# AVR32SD28 register map
Vendor: Atmel; File version: 1.0
CPU: other r0p0, little endian, no MPU, no FPU, 4 interrupt priority bits
Registers are 8-bit, read-write, reset 0x0 unless marked. A register's access mark holds for its fields unless they carry their own. Offsets are from the block's base; [hi:lo] are bit positions; {n}, {i} and the like mark numbered series; 'fields as' and 'values as' point back to an identical list.

## TWI0 — Two-Wire Interface
Base 0x00800900
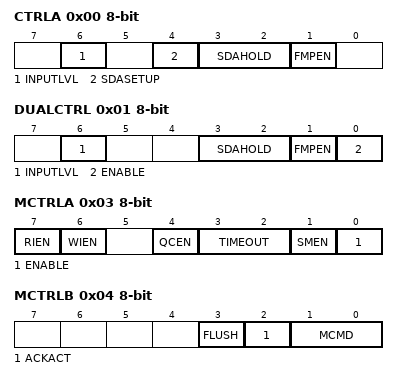
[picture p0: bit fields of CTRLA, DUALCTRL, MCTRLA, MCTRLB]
0x00 CTRLA — Control A
  [6] INPUTLVL — Input voltage transition level
    0=I2C (I2C input voltage transition level); 1=SMBUS (SMBus 3.0 input voltage transition level)
  [4] SDASETUP — SDA Setup Time
    0=4CYC (SDA setup time is four clock cycles); 1=8CYC (SDA setup time is eight clock cycle)
  [3:2] SDAHOLD — SDA Hold Time
    0=OFF (No SDA Hold Delay); 1=50NS (Short SDA hold time); 2=300NS (Meets SMBUS 2.0 specification under typical conditions); 3=500NS (Meets SMBUS 2.0 specificaiton across all corners)
  [1] FMPEN — Fast-mode Plus Enable
    0=OFF (Operating in Standard-mode or Fast-mode); 1=ON (Operating in Fast-mode Plus)
0x01 DUALCTRL — Dual Mode Control
  [6] INPUTLVL — Input voltage transition level
    values as CTRLA.INPUTLVL
  [3:2] SDAHOLD — SDA Hold Time
    values as CTRLA.SDAHOLD
  [1] FMPEN — Fast-mode Plus Enable
    values as CTRLA.FMPEN
  [0] ENABLE
0x02 DBGCTRL — Debug Control
  [0] DBGRUN — Debug Run
    0=HALT (The peripheral is halted in Break Debug mode and ignores events); 1=RUN (The peripheral will continue to run in Break Debug mode when the CPU is halted)
0x03 MCTRLA — Host Control A
  [7] RIEN — Read Interrupt Enable
  [6] WIEN — Write Interrupt Enable
  [4] QCEN — Quick Command Enable
  [3:2] TIMEOUT — Inactive Bus Time-Out
    0=DISABLED (Bus time-out disabled. I2C.); 1=50US (50us - SMBus); 2=100US; 3=200US
  [1] SMEN — Smart Mode Enable
  [0] ENABLE
0x04 MCTRLB — Host Control B
  [3] FLUSH
  [2] ACKACT — Acknowledge Action
    0=ACK (Send ACK); 1=NACK (Send NACK)
  [1:0] MCMD — Command
    0=NOACT (No action); 1=REPSTART (Execute Acknowledge Action followed by repeated Start.); 2=RECVTRANS (Execute Acknowledge Action followed by a byte read/write operation. Read/write is defined by DIR.); 3=STOP (Execute Acknowledge Action followed by issuing a Stop condition.)
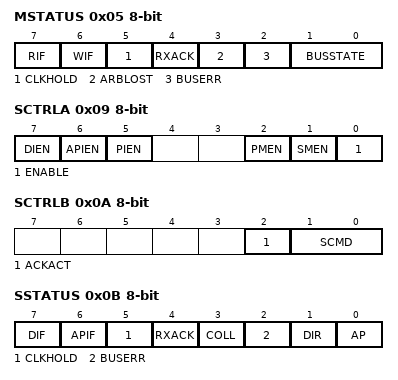
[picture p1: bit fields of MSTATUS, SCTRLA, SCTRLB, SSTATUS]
0x05 MSTATUS — Host STATUS
  [7] RIF — Read Interrupt Flag
  [6] WIF — Write Interrupt Flag
  [5] CLKHOLD — Clock Hold
  [4] RXACK ro — Received Acknowledge
  [3] ARBLOST — Arbitration Lost
  [2] BUSERR — Bus Error
  [1:0] BUSSTATE
    0=UNKNOWN (Unknown bus state); 1=IDLE (Bus is idle); 2=OWNER (This TWI controls the bus); 3=BUSY (The bus is busy)
0x06 MBAUD — Host Baud Rate
  [7:0] BAUD — Baud Rate
0x07 MADDR — Host Address
  [7:0] ADDR — Address
0x08 MDATA — Host Data
  [7:0] DATA
0x09 SCTRLA — Client Control A
  [7] DIEN — Data Interrupt Enable
  [6] APIEN — Address or Stop Interrupt Enable
  [5] PIEN — Stop Interrupt Enable
  [2] PMEN — Address Recognition Mode
  [1] SMEN — Smart Mode Enable
  [0] ENABLE
0x0A SCTRLB — Client Control B
  [2] ACKACT — Acknowledge Action
    0=ACK (Send ACK); 1=NACK (Send NACK)
  [1:0] SCMD — Command
    0=NOACT (No Action); 2=COMPTRANS (Complete transaction); 3=RESPONSE (Used in response to an interrupt)
0x0B SSTATUS — Client Status
  [7] DIF ro — Data Interrupt Flag
  [6] APIF ro — Address or Stop Interrupt Flag
  [5] CLKHOLD ro — Clock Hold
  [4] RXACK ro — Received Acknowledge
  [3] COLL — Collision
  [2] BUSERR — Bus Error
  [1] DIR ro — Read/Write Direction
  [0] AP ro — Address or Stop
    0=STOP (A Stop condition generated the interrupt on APIF flag); 1=ADR (Address detection generated the interrupt on APIF flag)
0x0C SADDR — Client Address
  [7:0] ADDR — Address
0x0D SDATA — Client Data
  [7:0] DATA
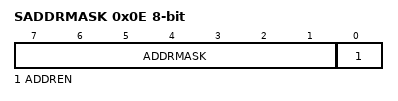
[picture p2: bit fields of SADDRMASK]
0x0E SADDRMASK — Client Address Mask
  [7:1] ADDRMASK — Address Mask
  [0] ADDREN — Address Mask Enable

## USART0 — Universal Synchronous and Asynchronous Receiver and Transmitter
Base 0x00800800
Same registers: USART1 0x00800820, USART2 0x00800840
0x00 RXDATAL ro — Receive Data Low Byte
  [7:0] DATA — RX Data
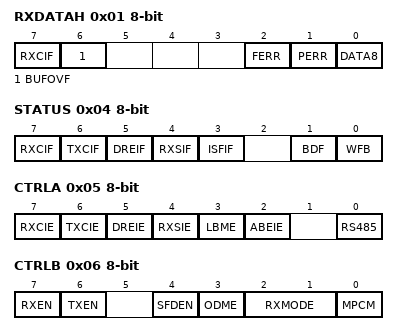
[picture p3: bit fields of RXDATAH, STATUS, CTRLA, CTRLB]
0x01 RXDATAH ro — Receive Data High Byte
  [7] RXCIF — Receive Complete Interrupt Flag
  [6] BUFOVF — Buffer Overflow
  [2] FERR — Frame Error
  [1] PERR — Parity Error
  [0] DATA8 — Receiver Data Register
0x02 TXDATAL — Transmit Data Low Byte
  [7:0] DATA — Transmit Data Register
0x03 TXDATAH — Transmit Data High Byte
  [0] DATA8 — Transmit Data Register (CHSIZE=9bit)
0x04 STATUS
  [7] RXCIF ro — Receive Complete Interrupt Flag
  [6] TXCIF — Transmit Interrupt Flag
  [5] DREIF ro — Data Register Empty Flag
  [4] RXSIF — Receive Start Interrupt
  [3] ISFIF — Inconsistent Sync Field Interrupt Flag
  [1] BDF — Break Detected Flag
  [0] WFB wo — Wait For Break
0x05 CTRLA — Control A
  [7] RXCIE — Receive Complete Interrupt Enable
  [6] TXCIE — Transmit Complete Interrupt Enable
  [5] DREIE — Data Register Empty Interrupt Enable
  [4] RXSIE — Receiver Start Frame Interrupt Enable
  [3] LBME — Loop-back Mode Enable
  [2] ABEIE — Auto-baud Error Interrupt Enable
  [0] RS485 — RS485 Mode internal transmitter
    0=DISABLE (RS485 Mode disabled); 1=ENABLE (RS485 Mode enabled)
0x06 CTRLB — Control B
  [7] RXEN — Reciever enable
  [6] TXEN — Transmitter Enable
  [4] SFDEN — Start Frame Detection Enable
  [3] ODME — Open Drain Mode Enable
  [2:1] RXMODE — Receiver Mode
    0=NORMAL (Normal mode); 1=CLK2X (CLK2x mode); 2=GENAUTO (Generic autobaud mode); 3=LINAUTO (LIN constrained autobaud mode)
  [0] MPCM — Multi-processor Communication Mode
0x07 CTRLC — Control C
  [7:6] CMODE — Communication Mode
    0=ASYNCHRONOUS (Asynchronous Mode); 1=SYNCHRONOUS (Synchronous Mode); 2=IRCOM (Infrared Communication); 3=MSPI (SPI Host Mode)
  [5:4] PMODE — Parity Mode
    0=DISABLED (No Parity); 2=EVEN (Even Parity); 3=ODD (Odd Parity)
  [3] SBMODE — Stop Bit Mode
    0=1BIT (1 stop bit); 1=2BIT (2 stop bits)
  [2] UDORD — SPI Host Mode, Data Order
  [1] UCPHA — SPI Host Mode, Clock Phase
  [2:0] CHSIZE — Character Size
    {v}={v+5}BIT (Character size: {v+5} bit) (v=0..3); 6=9BITL (Character size: 9 bit read low byte first); 7=9BITH (Character size: 9 bit read high byte first)
0x08 BAUD 16-bit (reset mask 0xFF) — Baud Rate
0x0A CTRLD — Control D
  [7:6] ABW — Auto Baud Window
    0=WDW0 (18% tolerance); 1=WDW1 (15% tolerance); 2=WDW2 (21% tolerance); 3=WDW3 (25% tolerance)
0x0B DBGCTRL — Debug Control
  [0] DBGRUN — Debug Run
0x0C EVCTRL — Event Control
  [0] IREI — IrDA Event Input Enable
0x0D TXPLCTRL — IRCOM Transmitter Pulse Length Control
  [7:0] TXPL — Transmit pulse length
0x0E RXPLCTRL — IRCOM Receiver Pulse Length Control
  [6:0] RXPL — Receiver Pulse Lenght

## VPORTA — Virtual Ports
Base 0x00800000
Same registers: VPORTC 0x00800008, VPORTD 0x0080000C, VPORTF 0x00800014
0x00 DIR — Data Direction
0x01 OUT — Output Value
0x02 IN — Input Value
0x03 INTFLAGS — Interrupt Flags
  [7:0] INT — Pin Interrupt Flag

## VREF — Voltage Reference
Base 0x00800072
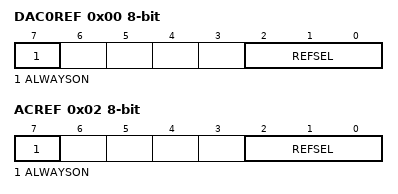
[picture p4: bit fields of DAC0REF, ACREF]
0x00 DAC0REF — DAC0 Reference
  [7] ALWAYSON
  [2:0] REFSEL — Reference select
    0=1V024 (Internal 1.024V reference); 1=2V048 (Internal 2.048V reference); 2=4V096 (Internal 4.096V reference); 3=2V500 (Internal 2.500V reference); 5=VDD (VDD as reference); 6=VREFA (External reference on VREFA pin)
0x02 ACREF — AC Reference
  fields as DAC0REF

## WDT — Watchdog Timer
Base 0x00800110
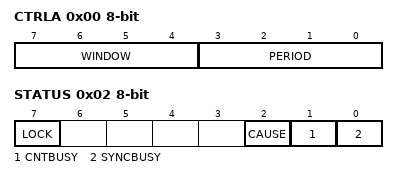
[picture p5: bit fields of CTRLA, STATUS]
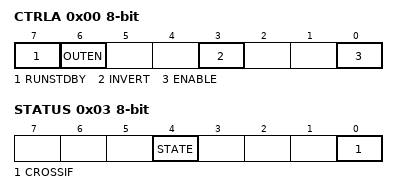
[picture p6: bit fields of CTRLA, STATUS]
0x00 CTRLA — Control A
  [7:4] WINDOW
    0=OFF; 1=8CLK (8 cycles (244 us)); 2=16CLK (16 cycles (488 us)); 3=32CLK (32 cycles (976 us)); 4=64CLK (64 cycles (1.95 ms)); 5=128CLK (128 cycles (3.9 ms)); 6=256CLK (256 cycles (7.8 ms)); 7=512CLK (512 cycles (15.625 ms)); 8=1KCLK (1K cycles (31.25 ms)); 9=2KCLK (2K cycles (62.5 ms)); 10=4KCLK (4K cycles (125 ms)); 11=8KCLK (8K cycles (250 ms))
  [3:0] PERIOD
    values as WINDOW
0x01 CTRLB ro — Control B
  [7:6] WDTMON — WDT Clock Monitor
    0=OFF (Monitor is disabled); 1=ON (Monitor is always on); 2=SLEEP (Monitor is always on in normal and IDLE mode, but automatically disabled when the MCU is in POWERDOWN and STANDBY sleep modes)
0x02 STATUS
  [7] LOCK — Lock enable
  [2] CAUSE ro — Reset Cause
    0=OUTSIDE (Outside window); 1=TIMEOUT
  [1] CNTBUSY ro — CNT Synchronization Busy
  [0] SYNCBUSY ro — Syncronization busy
0x04 CNT 16-bit ro (reset mask 0xFF) — Counter
  [13:0] CNT

## ZCD0 — Zero Cross Detect
Base 0x008006C0
Same registers: ZCD3 0x008006D8
0x00 CTRLA — Control A
  [7] RUNSTDBY — Run in Standby Mode
  [6] OUTEN — Output Pad Enable
  [3] INVERT — Invert signal from pin
  [0] ENABLE
0x02 INTCTRL — Interrupt Control
  [1:0] INTMODE — Interrupt Mode
    0=NONE (No interrupt); 1=RISING (Interrupt on rising input signal); 2=FALLING (Interrupt on falling input signal); 3=BOTH (Interrupt on both rising and falling input signal)
0x03 STATUS
  [4] STATE ro — ZCD State
    0=LOW (Output is 0); 1=HIGH (Output is 1)
  [0] CROSSIF — ZCD Interrupt Flag
